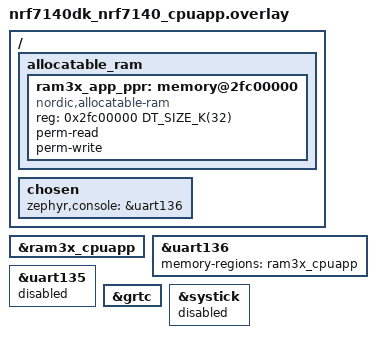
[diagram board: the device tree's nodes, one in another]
/*
 * Copyright (c) 2023 Nordic Semiconductor ASA
 *
 * SPDX-License-Identifier: LicenseRef-Nordic-5-Clause
 */

 /{
	allocatable_ram {
		#address-cells = <1>;
		#size-cells = <1>;

		/* Configure PPR memory region. Allow to use defined RAM3x
		 * region by App and cores owned by App.
		 */
		ram3x_app_ppr: memory@2fc00000 {
			compatible = "nordic,allocatable-ram";
			reg = <0x2fc00000 DT_SIZE_K(32)>;
			perm-read;
			perm-write;
		};
	};

	chosen {
		zephyr,console = &uart136;
	};
};

/* ram3x_cpuapp buffer is used by App core UART driver. */
&ram3x_cpuapp {
	status = "okay";
};

&uart136 {
	status = "okay";
	memory-regions = <&ram3x_cpuapp>;
};

/* Configure PPR UART. */
&uart135 {
	status = "reserved";
};

&grtc {
	status = "okay";
};

/* Disable systick for App core, GRTC is used as tick source. */
&systick {
	status = "disabled";
};
